# TPCC register map
Vendor: Texas Instruments
Registers are 32-bit, read-write, reset values left out (the file's numbers can be read two ways) unless marked. A register's access mark holds for its fields unless they carry their own. Offsets are as the file gives them; [hi:lo] are bit positions; {n}, {i} and the like mark numbered series; 'fields as' and 'values as' point back to an identical list.

## TPCC (part 2 of 2)
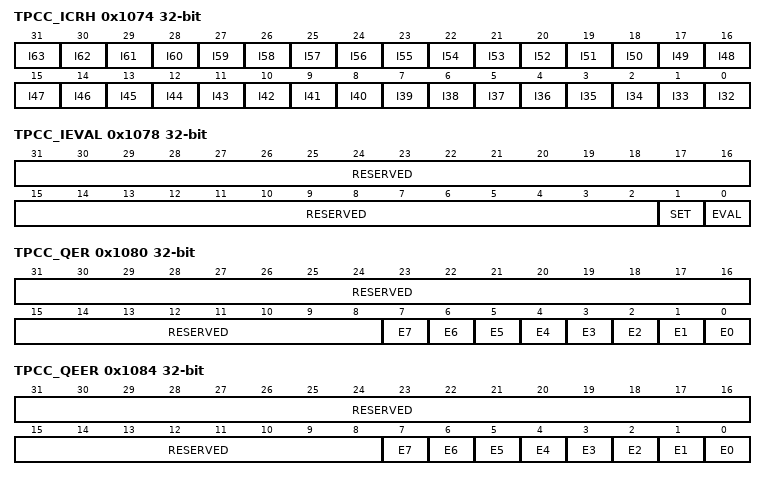
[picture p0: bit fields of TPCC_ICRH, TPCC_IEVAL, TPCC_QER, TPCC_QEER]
0x1074 TPCC_ICRH wo — Interrupt Clear Register (High Part):CPU write of 1 to the [n] In bit causes the [n] In bit to be cleared.CPU write of 0 has no effect.All [n] In bits must be cleared before additional interrupts will be asserted by CC.
  [n-32] I{n} (n=32..63) — Interrupt associated with TCC #{n}
0x1078 TPCC_IEVAL wo — Interrupt Eval Register
  [31:2] RESERVED — write 0's for future compatibility
  [1] SET — Interrupt Set:CPU write of 1 to the SETn bit causes the tpcc_intN output signal to be pulsed egardless of state of interrupts enable (IERn) and status (IPRn).CPU write of 0 has no effect.
  [0] EVAL — Interrupt Evaluate:CPU write of 1 to the EVALn bit causes the tpcc_intN output signal to be pulsed if any enabled interrupts (IERn) are still pending (IPRn).CPU write of 0 has no effect..
0x1080 TPCC_QER ro — QDMA Event Register:If [n] En bit is set, then the corresponding QDMA channel is prioritized vs. other qdma events for submission to the [n] En bit is set when a vbus write byte matches the address defined in the register. [n] En bit is cleared when the corresponding event is prioritized and serviced. [n] En is also cleared when user writes a 1 to the [n] En bit.If the [n] En bit is already set and a new QDMA event is detected due to user write to QDMA trigger location and register is set, then the corresponding bit in the QDMA Event Missed Register is set.
  [31:8] RESERVED — reads return 0's
  [n] E{n} (n=0..7) — Event #{n}
0x1084 TPCC_QEER ro — QDMA Event Enable Register:Enabled/disabled QDMA address comparator for QDMA Channel N. [n] En is not directly writeable.QDMA channels can be enabled via writes to and can be disabled via writes to register. [n] En = 1, The corresponding QDMA channel comparator is enabled and Events will be recognized and latched in [n] En. [n] En = 0, The corresponding QDMA channel comparator is disabled. Events will not be recognized/latched in [n] En.
  [31:8] RESERVED — reads return 0's
  [n] E{n} (n=0..7) — Event #{n}
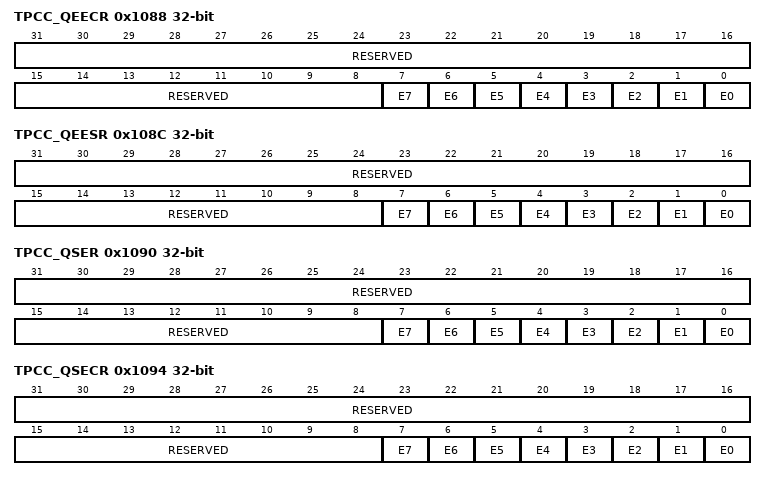
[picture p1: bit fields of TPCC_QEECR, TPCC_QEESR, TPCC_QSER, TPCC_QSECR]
0x1088 TPCC_QEECR wo — QDMA Event Enable Clear Register:CPU write of 1 to the [n] En bit causes the [n] En bit to be cleared.CPU write of 0 has no effect..
  [31:8] RESERVED — write 0's for future compatibility
  [n] E{n} (n=0..7) — Event #{n}
0x108C TPCC_QEESR wo — QDMA Event Enable Set Register:CPU write of 1 to the [n] En bit causes the [n] En bit to be set.CPU write of 0 has no effect..
  fields as TPCC_QEECR
0x1090 TPCC_QSER ro — QDMA Secondary Event Register:The QDMA secondary event register is used along with the QDMA Event Register () to provide information on the state of a QDMA Event.En = 0 : Event is not currently in the Event Queue.En = 1 : Event is currently stored in Event Queue.Event arbiter will not prioritize additional events.
  [31:8] RESERVED — reads return 0's
  [n] E{n} (n=0..7) — Event #{n}
0x1094 TPCC_QSECR wo — QDMA Secondary Event Clear Register:The secondary event clear register is used to clear the status of the and register (note that this is slightly different than the operation, which does not clear the [n] En register).CPU write of 1 to the [n] En bit clears the [n] En and [n] En register fields.CPU write of 0 has no effect..
  fields as TPCC_QEECR
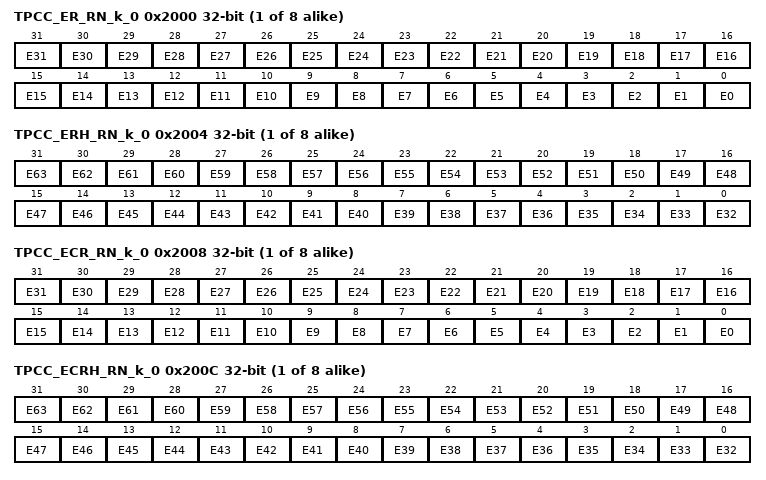
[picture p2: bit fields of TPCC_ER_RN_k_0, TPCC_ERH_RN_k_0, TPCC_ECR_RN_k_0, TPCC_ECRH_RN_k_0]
{0x2000+0x200*i} TPCC_ER_RN_k_{i} ro (i=0..7) — Event Register:If [n] En bit is set and the [n] En bit is also set, then the corresponding DMA channel is prioritized vs. other pending DMA events for submission to the [n] En bit is set when the input event #n transitions from inactive (low) to active (high), regardless of the state of [n] En bit. [n] En bit is cleared when the corresponding event is prioritized and serviced.If the [n] En bit is already set and a new inactive to active transition is detected on the input event #n input AND the corresponding bit in the register is set, then the corresponding bit in the Event Missed Register is set.Event N can be cleared via software by writing a 1 to the pseudo-register.
  [n] E{n} (n=0..31) — Event #{n}
{0x2004+0x200*i} TPCC_ERH_RN_k_{i} ro (i=0..7) — Event Register (High Part):If [n] En bit is set and the [n] En bit is also set, then the corresponding DMA channel is prioritized vs. other pending DMA events for submission to the TC. [n] En bit is set when the input event #n transitions from inactive (low) to active (high), regardless of the state of [n] En bit. [n] En bit is cleared when the corresponding event is prioritized and serviced.If the [n] En bit is already set and a new inactive to active transition is detected on the input event #n input AND the corresponding bit in the register is set, then the corresponding bit in the Event Missed Register is set.Event N can be cleared via software by writing a 1 to the pseudo-register.
  [n-32] E{n} (n=32..63) — Event #{n}
{0x2008+0x200*i} TPCC_ECR_RN_k_{i} wo (i=0..7) — Event Clear Register:CPU write of 1 to the [n] En bit causes the [n] En bit to be cleared.CPU write of 0 has no effect.
  [n] E{n} (n=0..31) — Event #{n}
{0x200C+0x200*i} TPCC_ECRH_RN_k_{i} wo (i=0..7) — Event Clear Register (High Part):CPU write of 1 to the [n] En bit causes the [n] En bit to be cleared.CPU write of 0 has no effect.
  [n-32] E{n} (n=32..63) — Event #{n}
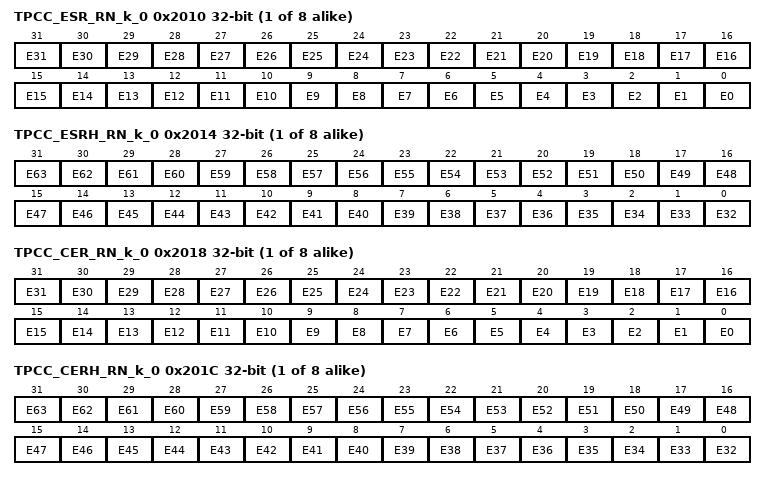
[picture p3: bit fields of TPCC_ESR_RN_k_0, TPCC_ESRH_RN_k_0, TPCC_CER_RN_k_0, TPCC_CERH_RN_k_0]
{0x2010+0x200*i} TPCC_ESR_RN_k_{i} wo (i=0..7) — Event Set Register:CPU write of 1 to the [n] En bit causes the [n] En bit to be set.CPU write of 0 has no effect.
  [n] E{n} (n=0..31) — Event #{n}
{0x2014+0x200*i} TPCC_ESRH_RN_k_{i} wo (i=0..7) — Event Set Register (High Part)CPU write of 1 to the [n] En bit causes the [n] En bit to be set.CPU write of 0 has no effect.
  [n-32] E{n} (n=32..63) — Event #{n}
{0x2018+0x200*i} TPCC_CER_RN_k_{i} ro (i=0..7) — Chained Event Register:If [n] En bit is set (regardless of state of [n] En), then the corresponding DMA channel is prioritized vs. other pending DMA events for submission to the [n] En bit is set when a chaining completion code is returned from one of the TPTCs via the completion interface, or is generated internally via Early Completion path. [n] En bit is cleared when the corresponding event is prioritized and serviced.If the [n] En bit is already set and the corresponding chaining completion code is returned from the TC, then the corresponding bit in the Event Missed Register is set. [n] En cannot be set or cleared via software.
  [n] E{n} (n=0..31) — Event #{n}
{0x201C+0x200*i} TPCC_CERH_RN_k_{i} ro (i=0..7) — Chained Event Register (High Part):If [n] En bit is set (regardless of state of [n] En), then the corresponding DMA channel is prioritized vs. other pending DMA events for submission to the [n] En bit is set when a chaining completion code is returned from one of the TPTCs via the completion interface, or is generated internally via Early Completion path. [n] bit is cleared when the corresponding event is prioritized and serviced.If the [n] bit is already set and the corresponding chaining completion code is returned from the TC, then the corresponding bit in the Event Missed Register is set. [n] cannot be set or cleared via software.
  [n-32] E{n} (n=32..63) — Event #{n}
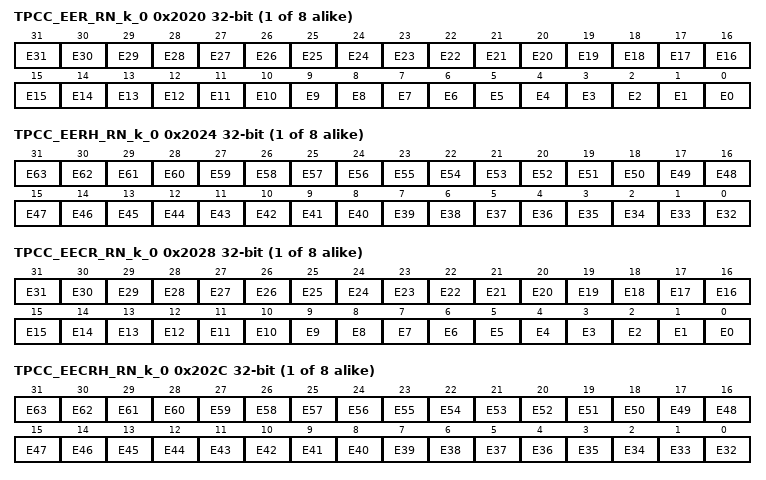
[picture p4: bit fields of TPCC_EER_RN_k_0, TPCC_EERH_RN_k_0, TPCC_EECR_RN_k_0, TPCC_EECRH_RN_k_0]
{0x2020+0x200*i} TPCC_EER_RN_k_{i} ro (i=0..7) — Event Enable Register:Enables DMA transfers for [n] En pending events. [n] En is set based on externally asserted events (via tpcc_eventN_pi). This register has no effect on Chained Event Register () or Event Set Register ().Note that if a bit is set in [n] En while [n] En is disabled, no action is taken.If [n] En is enabled at a later point (and [n] En has not been cleared via software) then the event will be recognized as a valid 'TR Sync' [n] En is not directly writeable.Events can be enabled via writes to and can be disabled via writes to register. [n] En = 0: [n] En is not enabled to trigger DMA transfers. [n] En = 1: [n] En is enabled to trigger DMA transfers.
  [n] E{n} (n=0..31) — Event #{n}
{0x2024+0x200*i} TPCC_EERH_RN_k_{i} ro (i=0..7) — Event Enable Register (High Part):Enables DMA transfers for [n] En pending events. [n] En is set based on externally asserted events (via tpcc_eventN_pi).This register has no effect on Chained Event Register () or Event Set Register ().Note that if a bit is set in [n] En while [n] En is disabled, no action is taken. If [n] En is enabled at a later point (and [n] En has not been cleared via software) then the event will be recognized as a valid 'TR Sync' [n] En is not directly writeable.Events can be enabled via writes to and can be disabled via writes to register. [n] En = 0: [n] En is not enabled to trigger DMA transfers. [n] En = 1: [n] En is enabled to trigger DMA transfers.
  [n-32] E{n} (n=32..63) — Event #{n}
{0x2028+0x200*i} TPCC_EECR_RN_k_{i} wo (i=0..7) — Event Enable Clear Register:CPU write of 1 to the [n] En bit causes the [n] En bit to be cleared.CPU write of 0 has no effect..
  [n] E{n} (n=0..31) — Event #{n}
{0x202C+0x200*i} TPCC_EECRH_RN_k_{i} wo (i=0..7) — Event Enable Clear Register (High Part):CPU write of 1 to the [n] En bit causes the [n] En bit to be cleared.CPU write of 0 has no effect..
  [n-32] E{n} (n=32..63) — Event #{n}
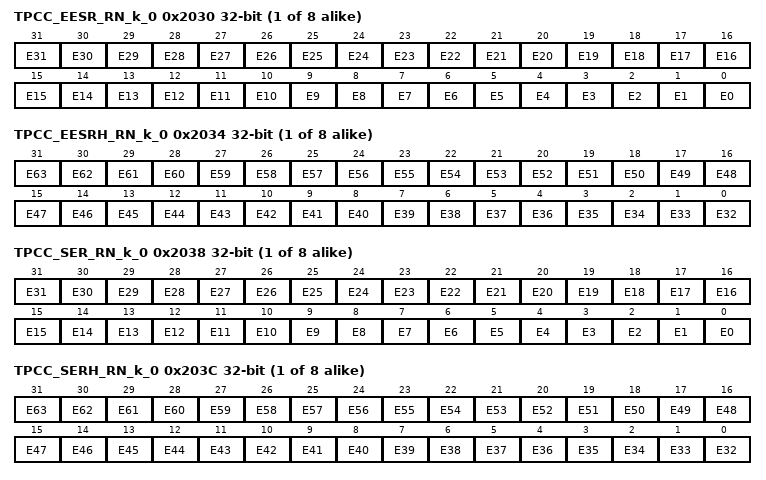
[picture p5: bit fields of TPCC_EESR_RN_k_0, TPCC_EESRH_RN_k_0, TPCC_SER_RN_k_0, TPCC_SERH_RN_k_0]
{0x2030+0x200*i} TPCC_EESR_RN_k_{i} wo (i=0..7) — Event Enable Set Register:CPU write of 1 to the [n] En bit causes the [n] En bit to be set.CPU write of 0 has no effect..
  [n] E{n} (n=0..31) — Event #{n}
{0x2034+0x200*i} TPCC_EESRH_RN_k_{i} wo (i=0..7) — Event Enable Set Register (High Part):CPU write of 1 to the [n] En bit causes the [n] En bit to be set.CPU write of 0 has no effect..
  [n-32] E{n} (n=32..63) — Event #{n}
{0x2038+0x200*i} TPCC_SER_RN_k_{i} ro (i=0..7) — Secondary Event Register:The secondary event register is used along with the Event Register () to provide information on the state of an Event.En = 0 : Event is not currently in the Event Queue.En = 1 : Event is currently stored in Event Queue.Event arbiter will not prioritize additional events.
  [n] E{n} (n=0..31) — Event #{n}
{0x203C+0x200*i} TPCC_SERH_RN_k_{i} ro (i=0..7) — Secondary Event Register (High Part):The secondary event register is used along with the Event Register () to provide information on the state of an Event.En = 0 : Event is not currently in the Event Queue.En = 1 : Event is currently stored in Event Queue.Event arbiter will not prioritize additional events.
  [n-32] E{n} (n=32..63) — Event #{n}
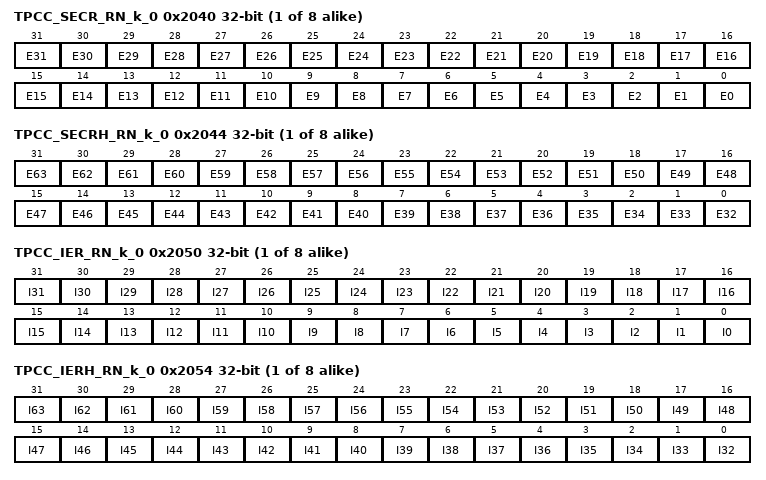
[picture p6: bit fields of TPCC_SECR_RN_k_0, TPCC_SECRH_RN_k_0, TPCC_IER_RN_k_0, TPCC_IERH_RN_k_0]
{0x2040+0x200*i} TPCC_SECR_RN_k_{i} wo (i=0..7) — Secondary Event Clear Register:The secondary event clear register is used to clear the status of the registers.CPU write of 1 to the [n] En bit clears the register.CPU write of 0 has no effect.
  [n] E{n} (n=0..31) — Event #{n}
{0x2044+0x200*i} TPCC_SECRH_RN_k_{i} wo (i=0..7) — Secondary Event Clear Register (High Part):The secondary event clear register is used to clear the status of the registers.CPU write of 1 to the [n] En bit clears the register.CPU write of 0 has no effect.
  [n-32] E{n} (n=32..63) — Event #{n}
{0x2050+0x200*i} TPCC_IER_RN_k_{i} ro (i=0..7) — Int Enable Register: [n] In is not directly writeable. Interrupts can be enabled via writes to and can be disabled via writes to register. [n] In = 0: [n] In is NOT enabled for interrupts. [n] In = 1: [n] In IS enabled for interrupts.
  [n] I{n} (n=0..31) — Interrupt associated with TCC #{n}
{0x2054+0x200*i} TPCC_IERH_RN_k_{i} ro (i=0..7) — Int Enable Register (High Part): [n] In is not directly writeable.Interrupts can be enabled via writes to and can be disabled via writes to register. [n] In = 0: [n] In is NOT enabled for interrupts. [n] In = 1: [n] In IS enabled for interrupts.
  [n-32] I{n} (n=32..63) — Interrupt associated with TCC #{n}
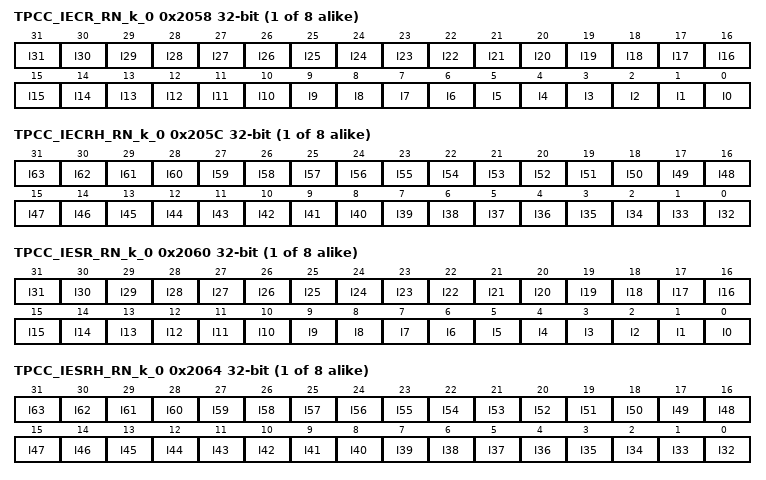
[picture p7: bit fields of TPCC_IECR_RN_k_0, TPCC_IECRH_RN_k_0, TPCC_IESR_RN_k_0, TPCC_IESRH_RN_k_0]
{0x2058+0x200*i} TPCC_IECR_RN_k_{i} wo (i=0..7) — Int Enable Clear Register:CPU write of 1 to the [n] In bit causes the [n] In bit to be cleared.CPU write of 0 has no effect..
  [n] I{n} (n=0..31) — Interrupt associated with TCC #{n}
{0x205C+0x200*i} TPCC_IECRH_RN_k_{i} wo (i=0..7) — Int Enable Clear Register (High Part):CPU write of 1 to the [n] In bit causes the [n] In bit to be cleared.CPU write of 0 has no effect..
  [n-32] I{n} (n=32..63) — Interrupt associated with TCC #{n}
{0x2060+0x200*i} TPCC_IESR_RN_k_{i} wo (i=0..7) — Int Enable Set Register:CPU write of 1 to the [n] In bit causes the [n] In bit to be set.CPU write of 0 has no effect..
  [n] I{n} (n=0..31) — Interrupt associated with TCC #{n}
{0x2064+0x200*i} TPCC_IESRH_RN_k_{i} wo (i=0..7) — Int Enable Set Register (High Part):CPU write of 1 to the [n] In bit causes the [n] In bit to be set.CPU write of 0 has no effect..
  [n-32] I{n} (n=32..63) — Interrupt associated with TCC #{n}
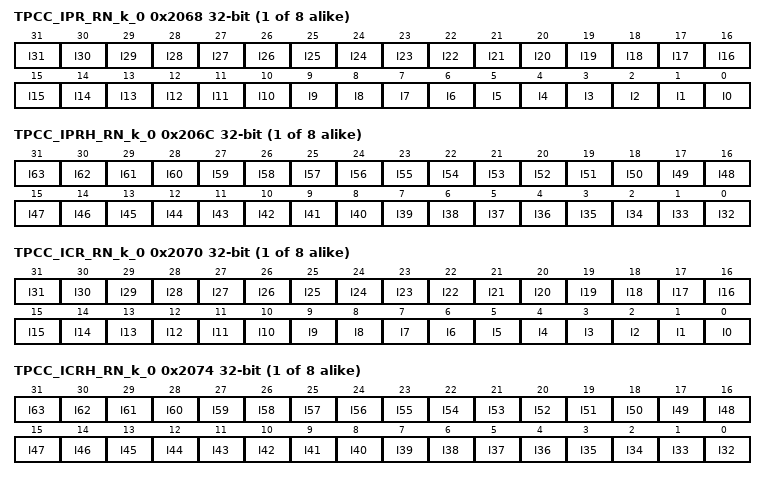
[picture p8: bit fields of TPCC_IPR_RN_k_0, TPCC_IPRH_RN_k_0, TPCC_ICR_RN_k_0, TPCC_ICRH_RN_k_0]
{0x2068+0x200*i} TPCC_IPR_RN_k_{i} ro (i=0..7) — Interrupt Pending Register: [n] In bit is set when a interrupt completion code with TCC of N is detected. [n] In bit is cleared via software by writing a 1 to [n] In bit.
  [n] I{n} (n=0..31) — Interrupt associated with TCC #{n}
{0x206C+0x200*i} TPCC_IPRH_RN_k_{i} ro (i=0..7) — Interrupt Pending Register (High Part): [n] In bit is set when a interrupt completion code with TCC of N is detected. [n] In bit is cleared via software by writing a 1 to [n] In bit.
  [n-32] I{n} (n=32..63) — Interrupt associated with TCC #{n}
{0x2070+0x200*i} TPCC_ICR_RN_k_{i} wo (i=0..7) — Interrupt Clear Register:CPU write of 1 to the [n] In bit causes the [n] In bit to be cleared.CPU write of 0 has no effect. All [n] In bits must be cleared before additional interrupts will be asserted by CC.
  [n] I{n} (n=0..31) — Interrupt associated with TCC #{n}
{0x2074+0x200*i} TPCC_ICRH_RN_k_{i} wo (i=0..7) — Interrupt Clear Register (High Part):CPU write of 1 to the [n] In bit causes the [n] In bit to be cleared.CPU write of 0 has no effect.All [n] In bits must be cleared before additional interrupts will be asserted by CC.
  [n-32] I{n} (n=32..63) — Interrupt associated with TCC #{n}
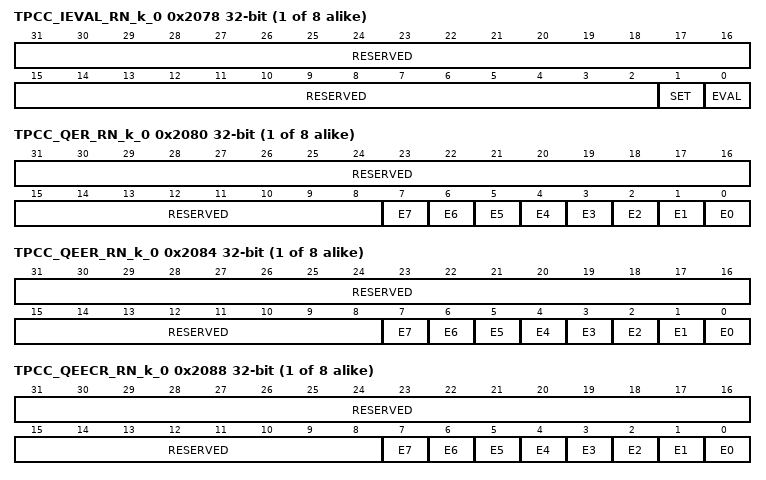
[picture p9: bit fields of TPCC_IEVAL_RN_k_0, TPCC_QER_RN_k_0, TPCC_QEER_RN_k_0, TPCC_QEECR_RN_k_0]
{0x2078+0x200*i} TPCC_IEVAL_RN_k_{i} wo (i=0..7) — Interrupt Eval Register
  fields as TPCC_IEVAL
{0x2080+0x200*i} TPCC_QER_RN_k_{i} ro (i=0..7) — QDMA Event Register:If [n] En bit is set, then the corresponding QDMA channel is prioritized vs. other qdma events for submission to the [n] En bit is set when a vbus write byte matches the address defined in the register. [n] En bit is cleared when the corresponding event is prioritized and serviced. [n] En is also cleared when user writes a 1 to the [n] En bit.If the [n] En bit is already set and a new QDMA event is detected due to user write to QDMA trigger location and register is set, then the corresponding bit in the QDMA Event Missed Register is set.
  [31:8] RESERVED — reads return 0's
  [n] E{n} (n=0..7) — Event #{n}
{0x2084+0x200*i} TPCC_QEER_RN_k_{i} ro (i=0..7) — QDMA Event Enable Register:Enabled/disabled QDMA address comparator for QDMA Channel N. [n] En is not directly writeable.QDMA channels can be enabled via writes to and can be disabled via writes to register. [n] En = 1, The corresponding QDMA channel comparator is enabled and Events will be recognized and latched in [n] En. [n] En = 0, The corresponding QDMA channel comparator is disabled. Events will not be recognized/latched in [n] En.
  [31:8] RESERVED — reads return 0's
  [n] E{n} (n=0..7) — Event #{n}
{0x2088+0x200*i} TPCC_QEECR_RN_k_{i} wo (i=0..7) — QDMA Event Enable Clear Register:CPU write of 1 to the [n] En bit causes the [n] En bit to be cleared.CPU write of 0 has no effect..
  fields as TPCC_QEECR
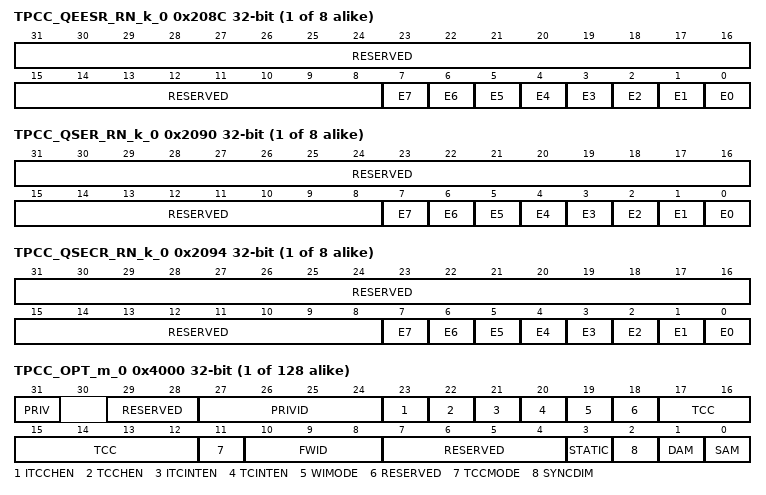
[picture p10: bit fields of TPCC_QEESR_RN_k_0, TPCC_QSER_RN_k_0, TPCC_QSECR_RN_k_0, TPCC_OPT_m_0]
{0x208C+0x200*i} TPCC_QEESR_RN_k_{i} wo (i=0..7) — QDMA Event Enable Set Register:CPU write of 1 to the [n] En bit causes the [n] En bit to be set.CPU write of 0 has no effect..
  fields as TPCC_QEECR
{0x2090+0x200*i} TPCC_QSER_RN_k_{i} ro (i=0..7) — QDMA Secondary Event Register:The QDMA secondary event register is used along with the QDMA Event Register () to provide information on the state of a QDMA Event.En = 0 : Event is not currently in the Event Queue.En = 1 : Event is currently stored in Event Queue.Event arbiter will not prioritize additional events.
  [31:8] RESERVED — reads return 0's
  [n] E{n} (n=0..7) — Event #{n}
{0x2094+0x200*i} TPCC_QSECR_RN_k_{i} wo (i=0..7) — QDMA Secondary Event Clear Register:The secondary event clear register is used to clear the status of the and register (note that this is slightly different than the operation, which does not clear the [n] En register).CPU write of 1 to the [n] En bit clears the [n] En and [n] En register fields.CPU write of 0 has no effect..
  fields as TPCC_QEECR
{0x4000+0x20*i} TPCC_OPT_m_{i} access per field (i=0..127) — Options Parameter
  [31] PRIV ro — Privilege level:privilege level (supervisor vs. user) for the host/cpu/dma that programmed this PaRAM Entry. Value is set with the vbus priv value when any part of the PaRAM Entry is written. Not writeable via vbus wdata bus. Is readable via VBus rdata bus.0 : User level privilege1 : Supervisor level privilege
  [29:28] RESERVED rw — write 0's for future compatibility reads return 0's
  [27:24] PRIVID ro — Privilege ID:Privilege ID for the external host/cpu/dma that programmed this PaRAM Entry. This value is set with the vbus privid value when any part of the PaRAM Entry is written. Not writeable via vbus wdata bus. Is readable via VBus rdata bus.
  [23] ITCCHEN rw — Intermediate transfer completion chaining enable:0: disabled1: enabled.
  [22] TCCHEN rw — Transfer complete chaining enable:0: disabled1: enabled.
  [21] ITCINTEN rw — Intermediate transfer completion interrupt enable:0: disabled.1: enabled (corresponding TPCC_IER bit must be set to 1 to generate interrupt)
  [20] TCINTEN rw — Transfer complete interrupt enable:0: disabled.1: enabled (corresponding TPCC_IER bit must be set to 1 to generate interrupt)
  [19] WIMODE rw — Backward compatibility mode:0: Normal operation1 : WI Backwards Compatibility mode, forces BCNT to be adjusted by 1 upon TR submission (0 means 1, 1 means 2, ... ) and forces ACNT to be treated as a word-count (left shifted by 2 by hardware to create byte cnt for TR submission)
  [18] RESERVED rw — write 0's for future compatibility reads return 0's
  [17:12] TCC rw — Transfer Complete Code:The 6-bit code is used to set the relevant bit in TPCC_CER for chaining or in TPCC_IER for interrupts.
  [11] TCCMODE rw — Transfer complete code mode:Indicates the point at which a transfer is considered completed. Applies to both chaining and interrupt.0: Normal Completion, A transfer is considered completed after the transfer parameters are returned to the CC from the TC (which was returned from the peripheral).1: Early Completion, A transfer is considered completed after the CC submits a TR to the TC. CC generates completion code internally .
  [10:8] FWID rw — FIFO width:Applies if either SAM or DAM is set to FIFO mode. Pass-thru to TC.
    0=FIFO width is 8-bit; 1=FIFO width is 16-bit; 2=FIFO width is 32-bit; 3=FIFO width is 64-bit; 4=FIFO width is 128-bit; 5=FIFO width is 256-bit
  [7:4] RESERVED rw — write 0's for future compatibility reads return 0's
  [3] STATIC rw — Static Entry:0: Entry is updated as normal1: Entry is static, Count and Address updates are not updated after TRP is submitted. Linking is not performed.
  [2] SYNCDIM rw — Transfer Synchronization Dimension:0: A-Sync, Each event triggers the transfer of ACNT elements.1: AB-Sync, Each event triggers the transfer of BCNT arrays of ACNT elements
  [1] DAM rw — Destination Address Mode:Destination Address Mode within an array. Pass-thru to TC.0: INCR, Dst addressing within an array increments. Dst is not a FIFO.1: FIFO, Dst addressing within an array wraps around upon reaching FIFO width.
  [0] SAM rw — Source Address Mode:Source Address Mode within an array. Pass-thru to TC.0: INCR, Src addressing within an array increments. Source is not a FIFO.1: FIFO, Src addressing within an array wraps around upon reaching FIFO width.
{0x4004+0x20*i} TPCC_SRC_m_{i} (i=0..127) — Source Address
  [31:0] SRC — Source Address:The 32-bit source address parameters specify the starting byte address of the source . If SAM is set to FIFO mode then the user should program the Source address to be aligned to the value specified by the OPT.FWID field. No errors are recognized here but TC will assert error if this is not true.
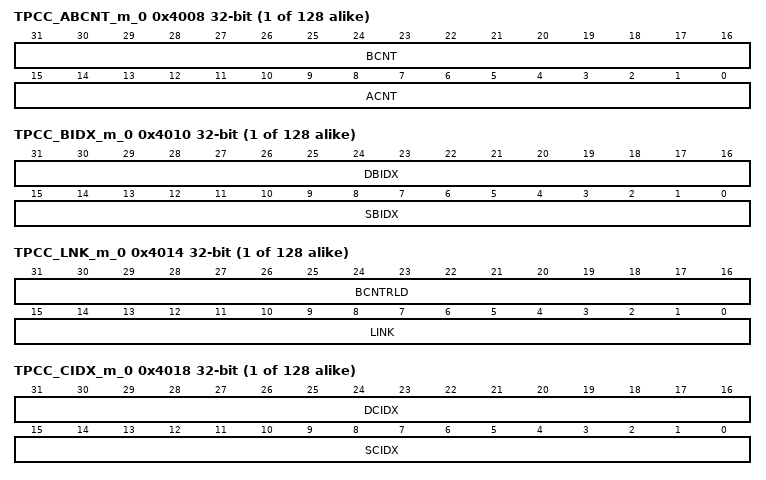
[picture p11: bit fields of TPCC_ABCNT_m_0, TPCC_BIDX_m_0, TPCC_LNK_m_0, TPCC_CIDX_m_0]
{0x4008+0x20*i} TPCC_ABCNT_m_{i} (i=0..127) — A and B byte count
  [31:16] BCNT — Count for 2nd Dimension:BCNT is a 16-bit unsigned value that specifies the number of arrays of length ACNT. For normal operation, valid values for BCNT can be anywhere between 1 and 65535. Therefore, the maximum number of arrays in a frame is 65535 (64K-1 arrays).BCNT=1 means 1 array in the frame, and BCNT=0 means 0 arrays in the frame. In normal mode, a BCNT of 0 is considered as either a Null or Dummy transfer. A Dummy or Null transfer will generate a Completion code depending on the settings of the completion bit fields of the OPT field. If the OPT.WIMODE bit is set, then the programmed BCNT value will be incremented by 1 before submission to TC. that is, 0 means 1, 1 means 2, 2 means 3, ..., 0xFFFE means 0xFFFF. A value of 0xFFFF is an illegal value that will be treated as a Null TR.
  [15:0] ACNT — number of bytes in 1st dimension:ACNT represents the number of bytes within the first dimension of a transfer. ACNT is a 16-bit unsigned value with valid values between 0 and 65535. Therefore, the maximum number of bytes in an array is 65535 bytes (64K-1 bytes). ACNT must be greater than or equal to 1 for a TR to be submitted to TC. An ACNT of 0 is considered as either a null or dummy transfer. A Dummy or Null transfer will generate a Completion code depending on the settings of the completion bit fields of the OPT field. If the OPT.WIMODE bit is set then the ACNT field represents a word count. The CC must internally multiply by 4 to translate the word count to a byte count prior to submission to the TC. The 2 MSBs of the 16-bit ACNT are reserved and should always be written as 'b00 by the user. If user writes a value other than 0, it will still be treated as 0 since the multiply-by-4 operation (to translate between a word count and a byte count) will drop the 2 msbits. For dummy and null transfer definition, the ACNT definition will disregard the 2 msbits. that is, a programmed ACNT value of 0x8000 in WI-mode will be treated as 0 byte transfer, resulting in null or dummy operation dependent on the state of BCNT and CCNT.
{0x400C+0x20*i} TPCC_DST_m_{i} (i=0..127) — Destination Address
  [31:0] DST — Destination Address:The 32-bit destination address parameters specify the starting byte address of the destination. If DAM is set to FIFO mode then the user should program the Destination address to be aligned to the value specified by the OPT.FWID field. No errors are recognized here but TC will assert error if this is not true.
{0x4010+0x20*i} TPCC_BIDX_m_{i} (i=0..127)
  [31:16] DBIDX — Destination 2nd Dimension Index:DBIDX is a 16-bit signed value (2's complement) used for destination address modification in between each array in the 2nd dimension. It is a signed value between -32768 and 32767. It provides a byte address offset from the beginning of the destination array to the beginning of the next destination array within the current frame. It applies to both A-Sync and AB-Sync transfers.
  [15:0] SBIDX — Source 2nd Dimension Index:SBIDX is a 16-bit signed value (2's complement) used for source address modification in between each array in the 2nd dimension. It is a signed value between -32768 and 32767. It provides a byte address offset from the beginning of the source array to the beginning of the next source array. It applies to both A-sync and AB-sync transfers.
{0x4014+0x20*i} TPCC_LNK_m_{i} (i=0..127) — Link and Reload parameters
  [31:16] BCNTRLD — BCNT Reload:BCNTRLD is a 16-bit unsigned value used to reload the BCNT field once the last array in the 2nd dimension is transferred. This field is only used for A-Sync'ed transfers. In this case, the CC decrements the BCNT value by one on each TR submission. When BCNT (conceptually) reaches zero, then the CC decrements CCNT and uses the BCNTRLD value to reinitialize the BCNT value. For AB-synchronized transfers, the CC submits the BCNT in the TR and therefore the TC is responsible to keep track of BCNT, not thus BCNTRLD is a don't care field.
  [15:0] LINK — Link Address:The CC provides a mechanism to reload the current PaRAM Entry upon its natural termination (that is, after count fields are decremented to 0) with a new PaRAM Entry. This is called 'linking'. The 16-bit parameter LINK specifies the byte address offset in the PaRAM from which the CC loads/reloads the next PaRAM entry in the link. The CC should disregard the value in the upper 2 bits of the LINK field as well as the lower 5-bits of the LINK field. The upper two bits are ignored such that the user can program either the 'literal' byte address of the LINK parameter or the 'PaRAM base-relative' address of the link field. Therefore, if the user uses the literal address with a range from 0x4000 to 0x7FFF, it will be treated as a PaRAM-base-relative value of 0x0000 to 0x3FFF. The lower-5 bits are ignored and treated as 'b00000, thereby guaranteeing that all Link pointers point to a 32-byte aligned PaRAM entry. In the latter case (5-lsbs), behavior is undefined for the user (that is, don't have to test it). In the former case (2 msbs), user should be able to take advantage of this feature (that is, do have to test it). If a Link Update is requested to a PaRAM address that is beyond the actual range of implemented PaRAM, then the Link will be treated as a Null Linkand all 0s plus 0xFFFF will be written to the current entry location. A LINK value of 0xFFFF is referred to as a NULL link which should cause the CC to write 0x0 to all entries of the current PaRAM Entry except for the LINK field which is set to 0xFFFF. The Priv/Privid state is overwritten to 0x0 when linking. MSBs and LSBS should not be masked when comparing against the 0xFFFF value. that is, a value of 0x3FFE is a non-NULL PaRAM link field.
{0x4018+0x20*i} TPCC_CIDX_m_{i} (i=0..127)
  [31:16] DCIDX — Destination Frame Index:DCIDX is a 16-bit signed value (2's complement) used for destination address modification for the 3rd dimension. It is a signed value between -32768 and 32767. It provides a byte address offset from the beginning of the current array (pointed to by DST address) to the beginning of the first destination array in the next frame. It applies to both A-sync and AB-sync transfers. Note that when DCIDX is applied, the current array in an A-sync transfer is the last array in the frame, while the current array in a ABsync transfer is the first array in the frame.
  [15:0] SCIDX — Source Frame Index:SCIDX is a 16-bit signed value (2's complement) used for source address modification for the 3rd dimension. It is a signed value between -32768 and 32767. It provides a byte address offset from the beginning of the current array (pointed to by SRC address) to the beginning of the first source array in the next frame. It applies to both A-sync and AB-sync transfers. Note that when SCIDX is applied, the current array in an A-sync transfer is the last array in the frame, while the current array in a AB-sync transfer is the first array in the frame.
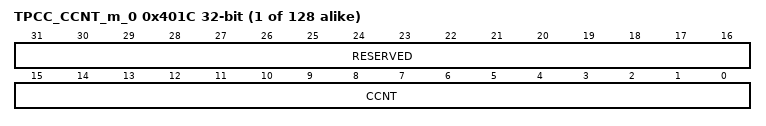
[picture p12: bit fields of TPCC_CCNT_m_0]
{0x401C+0x20*i} TPCC_CCNT_m_{i} (i=0..127) — C byte count
  [31:16] RESERVED — write 0's for future compatibility reads return 0's
  [15:0] CCNT — Count for 3rd Dimension:CCNT is a 16-bit unsigned value that specifies the number of frames in a block. Valid values for CCNT can be anywhere between 1 and 65535. Therefore, the maximum number of frames in a block is 65535 (64K-1 frames). CCNT of 1 means 1 frame in the block, and CCNT of 0 means 0 frames in the block. A CCNT value of 0 is considered as either a null or dummy transfer. A Dummy or Null transfer will generate a Completion code depending on the settings of the completion bit fields of the OPT field. WIMODE has no affect on CCNT operation.
